CM_ "IMPORT _bosch_2021.dbc";

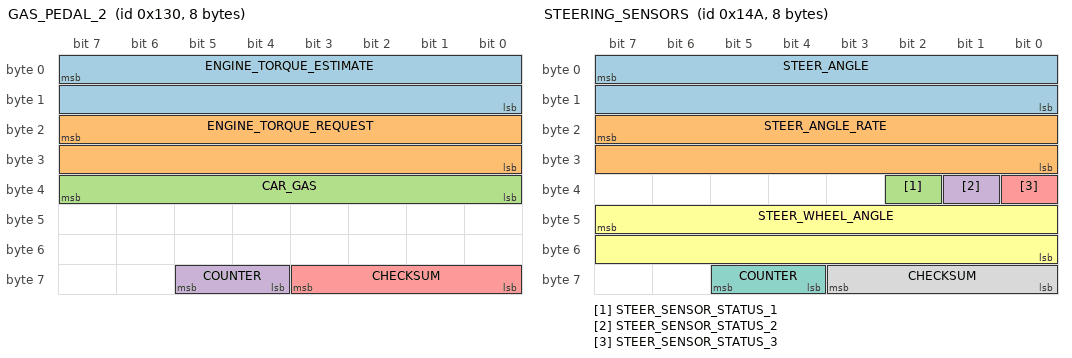
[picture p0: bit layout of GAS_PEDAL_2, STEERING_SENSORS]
BO_ 304 GAS_PEDAL_2: 8 PCM
 SG_ ENGINE_TORQUE_ESTIMATE : 7|16@0- (1,0) [-1000|1000] "Nm" EON
 SG_ ENGINE_TORQUE_REQUEST : 23|16@0- (1,0) [-1000|1000] "Nm" EON
 SG_ CAR_GAS : 39|8@0+ (1,0) [0|255] "" EON
 SG_ COUNTER : 61|2@0+ (1,0) [0|3] "" EON
 SG_ CHECKSUM : 59|4@0+ (1,0) [0|15] "" EON

BO_ 330 STEERING_SENSORS: 8 EPS
 SG_ STEER_ANGLE : 7|16@0- (-0.1,0) [-500|500] "deg" EON
 SG_ STEER_ANGLE_RATE : 23|16@0- (-1,0) [-3000|3000] "deg/s" EON
 SG_ STEER_SENSOR_STATUS_1 : 34|1@0+ (1,0) [0|1] "" EON
 SG_ STEER_SENSOR_STATUS_2 : 33|1@0+ (1,0) [0|1] "" EON
 SG_ STEER_SENSOR_STATUS_3 : 32|1@0+ (1,0) [0|1] "" EON
 SG_ STEER_WHEEL_ANGLE : 47|16@0- (-0.1,0) [-500|500] "deg" EON
 SG_ COUNTER : 61|2@0+ (1,0) [0|3] "" EON
 SG_ CHECKSUM : 59|4@0+ (1,0) [0|15] "" EON

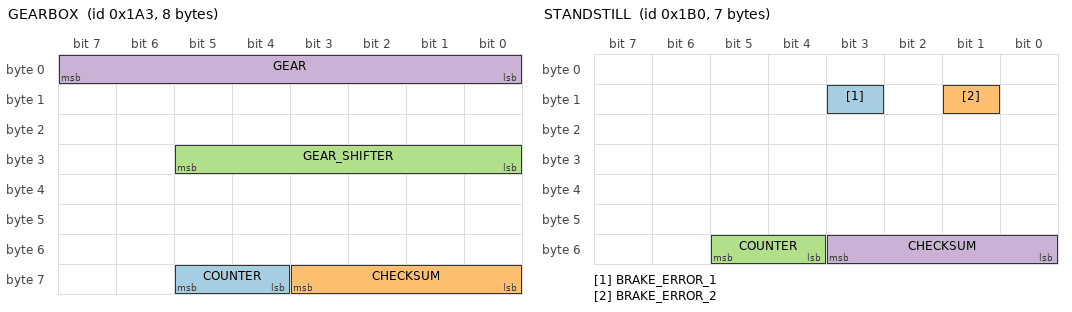
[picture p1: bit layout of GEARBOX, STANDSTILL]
BO_ 419 GEARBOX: 8 PCM
 SG_ COUNTER : 61|2@0+ (1,0) [0|3] "" EON
 SG_ CHECKSUM : 59|4@0+ (1,0) [0|3] "" EON
 SG_ GEAR_SHIFTER : 29|6@0+ (1,0) [0|63] "" EON
 SG_ GEAR : 7|8@0+ (1,0) [0|255] "" EON

BO_ 432 STANDSTILL: 7 VSA
 SG_ BRAKE_ERROR_1 : 11|1@0+ (1,0) [0|1] "" EON
 SG_ BRAKE_ERROR_2 : 9|1@0+ (1,0) [0|1] "" EON
 SG_ COUNTER : 53|2@0+ (1,0) [0|3] "" EON
 SG_ CHECKSUM : 51|4@0+ (1,0) [0|15] "" EON

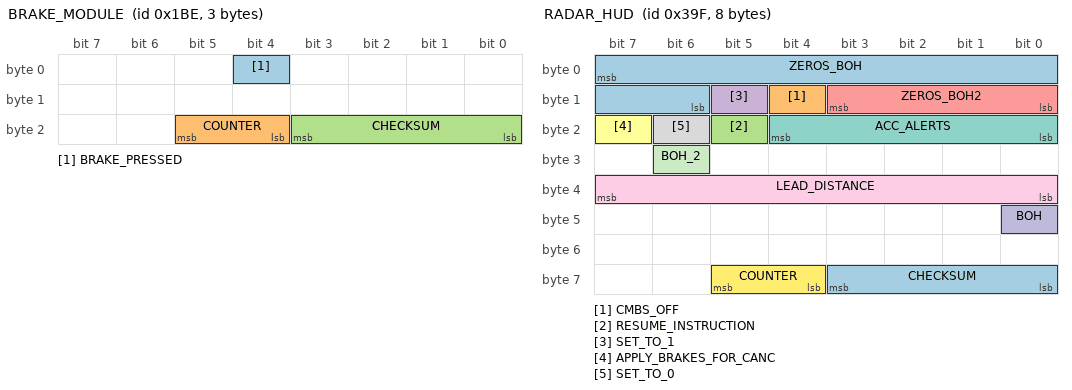
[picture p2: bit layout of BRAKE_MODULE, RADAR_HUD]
BO_ 446 BRAKE_MODULE: 3 VSA
 SG_ BRAKE_PRESSED : 4|1@0+ (1,0) [0|1] "" XXX
 SG_ COUNTER : 21|2@0+ (1,0) [0|3] "" XXX
 SG_ CHECKSUM : 19|4@0+ (1,0) [0|15] "" XXX

BO_ 927 RADAR_HUD: 8 RADAR
 SG_ ZEROS_BOH : 7|10@0+ (1,0) [0|127] "" BDY
 SG_ CMBS_OFF : 12|1@0+ (1,0) [0|1] "" BDY
 SG_ RESUME_INSTRUCTION : 21|1@0+ (1,0) [0|1] "" XXX
 SG_ SET_TO_1 : 13|1@0+ (1,0) [0|1] "" BDY
 SG_ ZEROS_BOH2 : 11|4@0+ (1,0) [0|1] "" XXX
 SG_ APPLY_BRAKES_FOR_CANC : 23|1@0+ (1,0) [0|1] "" XXX
 SG_ ACC_ALERTS : 20|5@0+ (1,0) [0|1] "" BDY
 SG_ SET_TO_0 : 22|1@0+ (1,0) [0|1] "" XXX
 SG_ LEAD_DISTANCE : 39|8@0+ (1,0) [0|255] "" XXX
 SG_ BOH : 40|1@0+ (1,0) [0|1] "" XXX
 SG_ BOH_2 : 30|1@0+ (1,0) [0|1] "" XXX
 SG_ COUNTER : 61|2@0+ (1,0) [0|3] "" XXX
 SG_ CHECKSUM : 59|4@0+ (1,0) [0|15] "" XXX

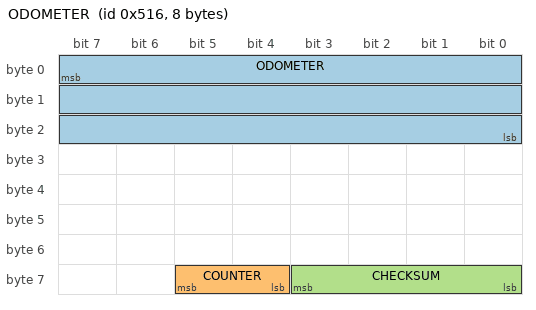
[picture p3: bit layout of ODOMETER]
BO_ 1302 ODOMETER: 8 XXX
 SG_ ODOMETER : 7|24@0+ (1,0) [0|16777215] "km" EON
 SG_ COUNTER : 61|2@0+ (1,0) [0|3] "" EON
 SG_ CHECKSUM : 59|4@0+ (1,0) [0|3] "" EON

VAL_ 419 GEAR_SHIFTER  32 "D" 8 "R" 4 "P" ;
VAL_ 545 ECON_ON_2 0 "off" 3 "on" ;
VAL_ 662 CRUISE_BUTTONS 7 "tbd" 6 "tbd" 5 "tbd" 4 "accel_res" 3 "decel_set" 2 "cancel" 1 "main" 0 "none" ;
VAL_ 662 CRUISE_SETTING 3 "distance_adj" 2 "tbd" 1 "lkas_button" 0 "none" ;
VAL_ 806 CMBS_BUTTON 3 "pressed" 0 "released" ;
VAL_ 891 WIPERS 4 "High" 2 "Low" 0 "Off" ;
VAL_ 829 BEEP 3 "single_beep" 2 "triple_beep" 1 "repeated_beep" 0 "no_beep" ;

CM_ "CHFFR_METRIC 330 STEER_ANGLE STEER_ANGLE 0.36 180; CHFFR_METRIC 380 ENGINE_RPM ENGINE_RPM 1 0; CHFFR_METRIC 804 ENGINE_TEMPERATURE ENGINE_TEMPERATURE 1 0";
